AUTOSAR XML (schema 00050)
package /PortInterfaces
  nv data interface NeBSWR_e_ShutOffPathTestStatus_prev
    nv-datas:
      data NeBSWR_e_ShutOffPathTestStatus_prev: category=VALUE, sw-calibration-access=READ-ONLY, type=uint8
  nv data interface NeSPT_AttemptsCounter
    nv-datas:
      data NeSPT_AttemptsCounter: category=VALUE, sw-calibration-access=READ-ONLY, type=uint8
  nv data interface NeSPT_SkippedOccurenceCounter
    nv-datas:
      data NeSPT_SkippedOccurenceCounter: category=VALUE, sw-calibration-access=READ-ONLY, type=uint8
package /SWC
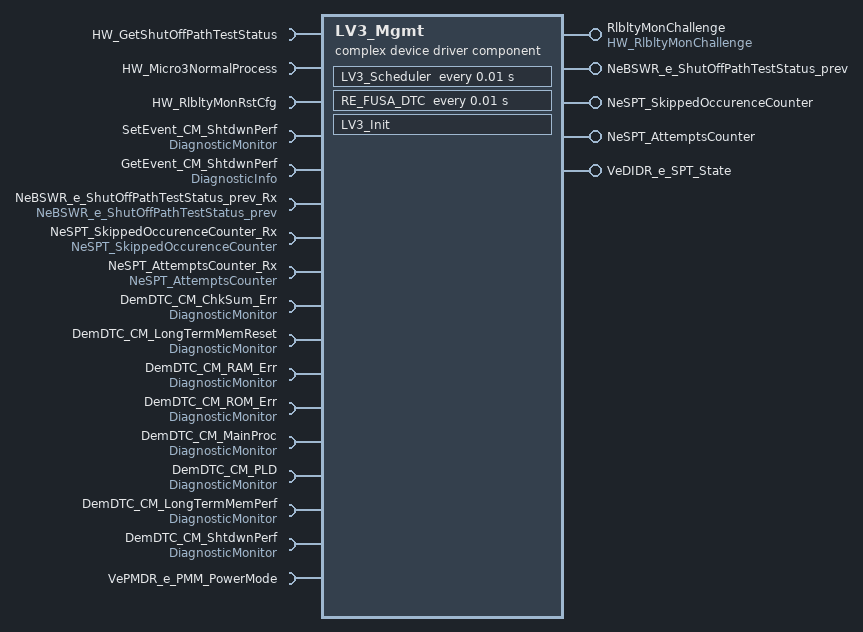
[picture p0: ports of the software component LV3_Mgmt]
  complex device driver sw component type LV3_Mgmt
    require port HW_GetShutOffPathTestStatus: required-interface=HW_GetShutOffPathTestStatus
    require port HW_Micro3NormalProcess: required-interface=HW_Micro3NormalProcess
    require port HW_RlbltyMonRstCfg: required-interface=HW_RlbltyMonRstCfg
    provide port RlbltyMonChallenge: provided-interface=HW_RlbltyMonChallenge
    require port SetEvent_CM_ShtdwnPerf: required-interface=DiagnosticMonitor
    require port GetEvent_CM_ShtdwnPerf: required-interface=DiagnosticInfo
    provide port NeBSWR_e_ShutOffPathTestStatus_prev: nv-provide-com-spec{ram-block-init-value=NumericalValueSpecification_0:0, rom-block-init-value=NumericalValueSpecification_0:0}, provided-interface=NeBSWR_e_ShutOffPathTestStatus_prev
    provide port NeSPT_SkippedOccurenceCounter: nv-provide-com-spec{ram-block-init-value=NumericalValueSpecification_0:0, rom-block-init-value=NumericalValueSpecification_0:0}, provided-interface=NeSPT_SkippedOccurenceCounter
    provide port NeSPT_AttemptsCounter: nv-provide-com-spec{ram-block-init-value=NumericalValueSpecification_0:0, rom-block-init-value=NumericalValueSpecification_0:0}, provided-interface=NeSPT_AttemptsCounter
    11 x require port:
      NeBSWR_e_ShutOffPathTestStatus_prev_Rx: nv-require-com-spec=init-value=NumericalValueSpecification_0:0, required-interface=NeBSWR_e_ShutOffPathTestStatus_prev
      NeSPT_SkippedOccurenceCounter_Rx: nv-require-com-spec=init-value=NumericalValueSpecification_0:0, required-interface=NeSPT_SkippedOccurenceCounter
      NeSPT_AttemptsCounter_Rx: nv-require-com-spec=init-value=NumericalValueSpecification_0:0, required-interface=NeSPT_AttemptsCounter
      DemDTC_CM_ChkSum_Err: required-interface=DiagnosticMonitor
      DemDTC_CM_LongTermMemReset: required-interface=DiagnosticMonitor
      DemDTC_CM_RAM_Err: required-interface=DiagnosticMonitor
      DemDTC_CM_ROM_Err: required-interface=DiagnosticMonitor
      DemDTC_CM_MainProc: required-interface=DiagnosticMonitor
      DemDTC_CM_PLD: required-interface=DiagnosticMonitor
      DemDTC_CM_LongTermMemPerf: required-interface=DiagnosticMonitor
      DemDTC_CM_ShtdwnPerf: required-interface=DiagnosticMonitor
    provide port VeDIDR_e_SPT_State: provided-interface=VeDIDR_e_SPT_State
    require port VePMDR_e_PMM_PowerMode: required-interface=VePMDR_e_PMM_PowerMode
    behavior IB_Lv3Mgmt: data-type-mapping=[ADTtoIDTMapping, ADTtoIDTMapping, ADTtoIDTMapping, msADTtoIDTMapping]
      timing event Event_LV3Scheduler: start-on-event=LV3_Scheduler, period=0.01
      timing event FUSA_DTC: start-on-event=RE_FUSA_DTC, period=0.01
      init event Event_LV3QandA: start-on-event=LV3_Init
      runnable LV3_Scheduler
        data-receive-point-by-arguments:
          4 x access:
            DRPA_NeSPT_SkippedOccurenceCounter_0: accessed-variable=NeSPT_SkippedOccurenceCounter_Rx.NeSPT_SkippedOccurenceCounter
            DRPA_NeBSWR_e_ShutOffPathTestStatus_prev_0: accessed-variable=NeBSWR_e_ShutOffPathTestStatus_prev_Rx.NeBSWR_e_ShutOffPathTestStatus_prev
            DRPA_NeSPT_AttemptsCounter_0: accessed-variable=NeSPT_AttemptsCounter_Rx.NeSPT_AttemptsCounter
            DSP_VePMDR_e_PMM_PowerMode: accessed-variable=VePMDR_e_PMM_PowerMode.Value
        data-send-points:
          4 x access:
            DSP_VeDIDR_e_SPT_State_0: accessed-variable=VeDIDR_e_SPT_State.VeDIDR_e_SPT_State
            DSP_NeBSWR_e_ShutOffPathTestStatus_prev_0: accessed-variable=NeBSWR_e_ShutOffPathTestStatus_prev.NeBSWR_e_ShutOffPathTestStatus_prev
            DSP_NeSPT_AttemptsCounter_0: accessed-variable=NeSPT_AttemptsCounter.NeSPT_AttemptsCounter
            DSP_NeSPT_SkippedOccurenceCounter_0: accessed-variable=NeSPT_SkippedOccurenceCounter.NeSPT_SkippedOccurenceCounter
        5 x sync call:
          SSCP_NormalProcess: operation=HW_Micro3NormalProcess.HW_Micro3NormalProcess
          SSCP_GetShutOffPathTestStatus: operation=HW_GetShutOffPathTestStatus.HW_GetShutOffPathTestStatus
          SetEvent_CM_ShtdwnPerf: operation=SetEvent_CM_ShtdwnPerf.SetEventStatus
          GetEvent_CM_ShtdwnPerf: operation=GetEvent_CM_ShtdwnPerf.GetEventStatus
          SSC_RlbltyMonGetWdgTiOut: operation=HW_RlbltyMonRstCfg.HW_RlbltyMonGetWdgTiOut
      runnable LV3_Init
        sync call SSC_RlbltyMonSetWdgTiOut: operation=HW_RlbltyMonRstCfg.HW_RlbltyMonSetWdgTiOut
      runnable RE_FUSA_DTC: symbol=RE_FUSA_DTC_func
        49 x sync call:
          SynchronousServerCallPoint_0: operation=DemDTC_CM_MainProc.SetEventStatus
          SynchronousServerCallPoint_1: operation=DemDTC_CM_MainProc.ResetEventStatus
          SynchronousServerCallPoint_2: operation=DemDTC_CM_MainProc.PrestoreFreezeFrame
          SynchronousServerCallPoint_3: operation=DemDTC_CM_MainProc.ClearPrestoredFreezeFrame
          SynchronousServerCallPoint_4: operation=DemDTC_CM_MainProc.ResetEventDebounceStatus
          SynchronousServerCallPoint_5: operation=DemDTC_CM_PLD.SetEventStatus
          SynchronousServerCallPoint_6: operation=DemDTC_CM_PLD.ResetEventStatus
          SynchronousServerCallPoint_7: operation=DemDTC_CM_PLD.PrestoreFreezeFrame
          SynchronousServerCallPoint_8: operation=DemDTC_CM_PLD.ClearPrestoredFreezeFrame
          SynchronousServerCallPoint_9: operation=DemDTC_CM_PLD.ResetEventDebounceStatus
          SynchronousServerCallPoint_10: operation=SetEvent_CM_ShtdwnPerf.SetEventStatus
          SynchronousServerCallPoint_11: operation=SetEvent_CM_ShtdwnPerf.ResetEventStatus
          SynchronousServerCallPoint_12: operation=SetEvent_CM_ShtdwnPerf.PrestoreFreezeFrame
          SynchronousServerCallPoint_13: operation=SetEvent_CM_ShtdwnPerf.ClearPrestoredFreezeFrame
          SynchronousServerCallPoint_14: operation=SetEvent_CM_ShtdwnPerf.ResetEventDebounceStatus
          SynchronousServerCallPoint_15: operation=DemDTC_CM_LongTermMemReset.SetEventStatus
          SynchronousServerCallPoint_16: operation=DemDTC_CM_LongTermMemReset.ResetEventStatus
          SynchronousServerCallPoint_17: operation=DemDTC_CM_LongTermMemReset.PrestoreFreezeFrame
          SynchronousServerCallPoint_18: operation=DemDTC_CM_LongTermMemReset.ClearPrestoredFreezeFrame
          SynchronousServerCallPoint_19: operation=DemDTC_CM_LongTermMemReset.ResetEventDebounceStatus
          SynchronousServerCallPoint_20: operation=GetEvent_CM_ShtdwnPerf.GetEventStatus
          SynchronousServerCallPoint_21: operation=GetEvent_CM_ShtdwnPerf.GetDTCOfEvent
          SynchronousServerCallPoint_22: operation=GetEvent_CM_ShtdwnPerf.GetDebouncingOfEvent
          SynchronousServerCallPoint_23: operation=GetEvent_CM_ShtdwnPerf.GetFaultDetectionCounter
          SynchronousServerCallPoint_24: operation=GetEvent_CM_ShtdwnPerf.GetEventExtendedDataRecord
          SynchronousServerCallPoint_25: operation=GetEvent_CM_ShtdwnPerf.GetEventExtendedDataRecordEx
          SynchronousServerCallPoint_26: operation=GetEvent_CM_ShtdwnPerf.GetEventFreezeFrameData
          SynchronousServerCallPoint_27: operation=GetEvent_CM_ShtdwnPerf.GetEventFreezeFrameDataEx
          SynchronousServerCallPoint_28: operation=GetEvent_CM_ShtdwnPerf.GetMonitorStatus
          SynchronousServerCallPoint_29: operation=DemDTC_CM_ROM_Err.SetEventStatus
          SynchronousServerCallPoint_30: operation=DemDTC_CM_ROM_Err.ResetEventStatus
          SynchronousServerCallPoint_31: operation=DemDTC_CM_ROM_Err.PrestoreFreezeFrame
          SynchronousServerCallPoint_32: operation=DemDTC_CM_ROM_Err.ClearPrestoredFreezeFrame
          SynchronousServerCallPoint_33: operation=DemDTC_CM_ROM_Err.ResetEventDebounceStatus
          SynchronousServerCallPoint_34: operation=DemDTC_CM_LongTermMemPerf.SetEventStatus
          SynchronousServerCallPoint_35: operation=DemDTC_CM_LongTermMemPerf.ResetEventStatus
          SynchronousServerCallPoint_36: operation=DemDTC_CM_LongTermMemPerf.PrestoreFreezeFrame
          SynchronousServerCallPoint_37: operation=DemDTC_CM_LongTermMemPerf.ClearPrestoredFreezeFrame
          SynchronousServerCallPoint_38: operation=DemDTC_CM_LongTermMemPerf.ResetEventDebounceStatus
          SynchronousServerCallPoint_39: operation=DemDTC_CM_ChkSum_Err.SetEventStatus
          SynchronousServerCallPoint_40: operation=DemDTC_CM_ChkSum_Err.ResetEventStatus
          SynchronousServerCallPoint_41: operation=DemDTC_CM_ChkSum_Err.PrestoreFreezeFrame
          SynchronousServerCallPoint_42: operation=DemDTC_CM_ChkSum_Err.ClearPrestoredFreezeFrame
          SynchronousServerCallPoint_43: operation=DemDTC_CM_ChkSum_Err.ResetEventDebounceStatus
          SynchronousServerCallPoint_44: operation=DemDTC_CM_RAM_Err.SetEventStatus
          SynchronousServerCallPoint_45: operation=DemDTC_CM_RAM_Err.ResetEventStatus
          SynchronousServerCallPoint_46: operation=DemDTC_CM_RAM_Err.PrestoreFreezeFrame
          SynchronousServerCallPoint_47: operation=DemDTC_CM_RAM_Err.ClearPrestoredFreezeFrame
          SynchronousServerCallPoint_48: operation=DemDTC_CM_RAM_Err.ResetEventDebounceStatus
      shared-parameters:
        5 x parameter data prototype, all with sw-calibration-access=READ-WRITE:
          KeSPT_EnableShutOffPathTest: type=boolean, init-value=NumericalValueSpecification_0:0
          KeHWIO_Lv3EnableQACommunication: type=boolean, init-value=NumericalValueSpecification_0:0
          Configure_Window_Size: type=uint8, init-value=NumericalValueSpecification_0:12
          KeSPT_SkipSPTFailThreshold: type=uint8, init-value=NumericalValueSpecification_0:0
          KeSPT_SkipSPTSampleThreshold: type=uint8, init-value=NumericalValueSpecification_0:0
